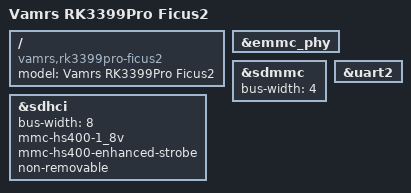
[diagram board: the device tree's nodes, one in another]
/*
 * (C) Copyright 2016 Rockchip Electronics Co., Ltd
 *
 * SPDX-License-Identifier:     GPL-2.0+
 */

/dts-v1/;
#include <dt-bindings/pwm/pwm.h>
#include <dt-bindings/pinctrl/rockchip.h>
#include "rk3399.dtsi"
#include "rk3399-sdram-lpddr3-4GB-1600.dtsi"
#include "rk3399-u-boot.dtsi"
#include <linux/media-bus-format.h>
#include <dt-bindings/input/input.h>

/ {
	model = "Vamrs RK3399Pro Ficus2";
	compatible = "vamrs,rk3399pro-ficus2", "rockchip,rk3399-evb",
		     "rockchip,rk3399", "google,rk3399evb-rev2";
};

&emmc_phy {
	status = "okay";
};

&sdhci {
	bus-width = <8>;
	mmc-hs400-1_8v;
	mmc-hs400-enhanced-strobe;
	non-removable;
	status = "okay";
};

&sdmmc {
	bus-width = <4>;
	status = "okay";
};

&uart2 {
	status = "okay";
};
